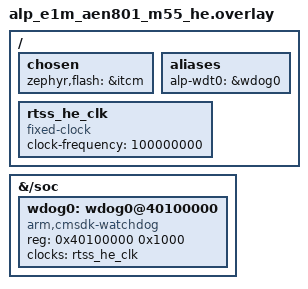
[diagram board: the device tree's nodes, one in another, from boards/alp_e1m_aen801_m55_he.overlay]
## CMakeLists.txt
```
# SPDX-License-Identifier: Apache-2.0
cmake_minimum_required(VERSION 3.20)
find_package(Zephyr REQUIRED HINTS $ENV{ZEPHYR_BASE})
project(aen_wdt_feed LANGUAGES C)
target_sources(app PRIVATE src/main.c)
```

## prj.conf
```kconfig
# SPDX-License-Identifier: Apache-2.0
#
# Bench RAM-run config for the E1M-AEN801 (M55-HE).

CONFIG_ALP_SDK=y

# Watchdog subsystem + the UPSTREAM CMSDK driver. CONFIG_WDOG_CMSDK_APB is
# `default y` once the wdog0 node is enabled (DT_HAS_ARM_CMSDK_WATCHDOG_ENABLED);
# it depends on RUNTIME_NMI (the CMSDK WDT signals via NMI).
CONFIG_WATCHDOG=y
CONFIG_RUNTIME_NMI=y

CONFIG_MAIN_STACK_SIZE=4096

# Console: Alp UART console -- E1M edge UART0 (Alif UART5, P3_4/P3_5, 115200
# 8N1, NS16550), the E1M-AEN801 carrier console. The board _defconfig already
# selects it; we set it explicitly here so the example is self-describing.
CONFIG_SERIAL=y
CONFIG_CONSOLE=y
CONFIG_UART_CONSOLE=y
CONFIG_UART_INTERRUPT_DRIVEN=y
# Serial-less bench? Comment the four lines above and uncomment these to read
# 'ram_console_buf' over SWD instead:
# CONFIG_RAM_CONSOLE=y
# CONFIG_RAM_CONSOLE_BUFFER_SIZE=2048
# CONFIG_UART_CONSOLE=n
CONFIG_PRINTK=y
```

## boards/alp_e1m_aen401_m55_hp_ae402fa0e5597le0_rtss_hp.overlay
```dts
/*
 * Copyright (c) 2026 Alp Lab AB
 * SPDX-License-Identifier: Apache-2.0
 *
 * CMSDK watchdog overlay for the E1M-AEN401 (E4, M55-HP).
 *
 * The board devicetree carries wdog0@40100000 (arm,cmsdk-watchdog) and its
 * clock, disabled (zephyr/dts/alif/ensemble_rtss_hp_wdog.dtsi); this overlay
 * only enables it and names it for the app.  Driver = UPSTREAM Zephyr
 * wdt_cmsdk_apb.c (Tier-1, NOT vendored).
 */

/ {
	chosen {
		zephyr,flash = &itcm; /* bench RAM/SES-load; path-ref form */
		/delete-property/ zephyr,code-partition;
	};
	aliases {
		alp-wdt0 = &wdog0;
	};
};

&wdog0 {
	status = "okay";
};
```

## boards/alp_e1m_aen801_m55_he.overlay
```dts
/*
 * Copyright (c) 2026 Alp Lab AB
 * SPDX-License-Identifier: Apache-2.0
 *
 * CMSDK watchdog overlay for the E1M-AEN801 (E8, M55-HE).
 *
 * wdog0@40100000 (compatible arm,cmsdk-watchdog) is transcribed from the
 * Apache-2.0 zephyr_alif fork (dts/arm/alif/ensemble RTSS-HE) -- the alp-sdk E8
 * SoC dtsi doesn't carry it, so it is created here.  Driver = UPSTREAM Zephyr
 * wdt_cmsdk_apb.c (Tier-1, NOT vendored).
 *
 * The driver reads its tick rate from the `clocks` phandle's `clock-frequency`
 * property at build time (DT_INST_PROP_BY_PHANDLE(0, clocks, clock_frequency)),
 * so we add a fixed-clock `rtss_he_clk` -- the same phandle the fork uses on the
 * HE core.  Its frequency is a TRM PLACEHOLDER: reload = timeout_ms * freq_khz,
 * so the API path is exact but the absolute timeout DURATION is unverified until
 * the real RTSS-HE watchdog clock is confirmed. [[project_pending_hw_configs]]
 */

/ {
	chosen {
		zephyr,flash = &itcm; /* bench RAM/SES-load; path-ref form */
		/delete-property/ zephyr,code-partition;
	};
	aliases {
		alp-wdt0 = &wdog0;
	};

	rtss_he_clk: rtss_he_clk {
		compatible = "fixed-clock";
		#clock-cells = <0>;
		clock-frequency = <100000000>; /* PLACEHOLDER; confirm vs TRM */
	};
};

&{/soc} {
	wdog0: wdog0@40100000 {
		compatible = "arm,cmsdk-watchdog";
		reg = <0x40100000 0x1000>;
		clocks = <&rtss_he_clk>;
		status = "okay";
	};
};
```

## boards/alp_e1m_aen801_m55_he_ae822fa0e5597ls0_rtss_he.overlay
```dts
/*
 * Copyright (c) 2026 Alp Lab AB
 * SPDX-License-Identifier: Apache-2.0
 *
 * CMSDK watchdog overlay for the E1M-AEN801 (E8, M55-HE).
 *
 * The board devicetree carries wdog0@40100000 (arm,cmsdk-watchdog) and its
 * clock, disabled (zephyr/dts/alif/ensemble_rtss_he_wdog.dtsi); this overlay
 * only enables it and names it for the app.  Driver = UPSTREAM Zephyr
 * wdt_cmsdk_apb.c (Tier-1, NOT vendored).
 */

/ {
	chosen {
		zephyr,flash = &itcm; /* bench RAM/SES-load; path-ref form */
		/delete-property/ zephyr,code-partition;
	};
	aliases {
		alp-wdt0 = &wdog0;
	};
};

&wdog0 {
	status = "okay";
};
```

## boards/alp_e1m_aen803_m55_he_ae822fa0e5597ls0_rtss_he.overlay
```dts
/*
 * Copyright (c) 2026 Alp Lab AB
 * SPDX-License-Identifier: Apache-2.0
 *
 * CMSDK watchdog overlay for the E1M-AEN803 (E8, M55-HE).
 *
 * The board devicetree carries wdog0@40100000 (arm,cmsdk-watchdog) and its
 * clock, disabled (zephyr/dts/alif/ensemble_rtss_he_wdog.dtsi); this overlay
 * only enables it and names it for the app.  Driver = UPSTREAM Zephyr
 * wdt_cmsdk_apb.c (Tier-1, NOT vendored).
 */

/ {
	chosen {
		zephyr,flash = &itcm; /* bench RAM/SES-load; path-ref form */
		/delete-property/ zephyr,code-partition;
	};
	aliases {
		alp-wdt0 = &wdog0;
	};
};

&wdog0 {
	status = "okay";
};
```

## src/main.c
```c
/*
 * Copyright (c) 2026 Alp Lab AB
 * SPDX-License-Identifier: Apache-2.0
 *
 * aen-wdt-feed -- install + feed the Ensemble E4 / E8 CMSDK watchdog on the
 * E1M-AEN801/803 (M55-HE) or E1M-AEN401 (M55-HP), via the UPSTREAM Zephyr
 * wdt_cmsdk_apb driver (Tier-1, no vendoring -- "arm,cmsdk-watchdog").  Drives
 * the standard Zephyr watchdog API (wdt_install_timeout / wdt_setup / wdt_feed /
 * wdt_disable) on DT_ALIAS(alp_wdt0) = &wdog0.
 *
 * The watchdog is the safety belt: if the main loop hangs, the WDT resets the
 * SoC back to a known-good state.  This example installs a timeout, feeds it a
 * few times, then DISABLES it -- it never lets the timeout actually fire (a
 * reset would re-boot the SES and tear down the bench RAM-console read).
 *
 * PASS gate: device ready, wdt_install_timeout + wdt_setup + every wdt_feed
 * return 0, and wdt_disable returns 0 (the WDT was running and got stopped
 * cleanly).  NOTE: the exact timeout duration depends on the watchdog clock
 * rate, which is a TRM placeholder here -- the API path is what this proves.
 */

#include <stdio.h>

#include <alp/peripheral.h>
#include <zephyr/device.h>
#include <zephyr/drivers/watchdog.h>

#define WDT_NODE       DT_ALIAS(alp_wdt0)
#define WDT_TIMEOUT_MS 8000
#define FEEDS          5
#define FEED_PERIOD_MS 300

int main(void)
{
	const struct device *wdt = DEVICE_DT_GET(WDT_NODE);

	printf("[wdt] open %s (CMSDK watchdog, timeout=%u ms)\n", wdt->name, WDT_TIMEOUT_MS);
	if (!device_is_ready(wdt)) {
		printf("[wdt] RESULT FAIL: device not ready\n[wdt] done\n");
		return 0;
	}

	struct wdt_timeout_cfg cfg = {
		.window   = { .min = 0, .max = WDT_TIMEOUT_MS },
		.callback = NULL,
		.flags    = WDT_FLAG_RESET_SOC,
	};
	int ch = wdt_install_timeout(wdt, &cfg);
	printf("[wdt] wdt_install_timeout -> %d\n", ch);
	if (ch < 0) {
		printf("[wdt] RESULT FAIL: install rc=%d\n[wdt] done\n", ch);
		return 0;
	}

	/* PAUSE_HALTED_BY_DBG so the SWD halt used to read the console doesn't
	 * trip the watchdog mid-debug. */
	int rc = wdt_setup(wdt, WDT_OPT_PAUSE_HALTED_BY_DBG);
	printf("[wdt] wdt_setup -> %d\n", rc);
	if (rc != 0) {
		printf("[wdt] RESULT FAIL: setup rc=%d\n[wdt] done\n", rc);
		return 0;
	}

	int fed = 0;
	for (int i = 0; i < FEEDS; i++) {
		alp_delay_ms(FEED_PERIOD_MS);
		rc = wdt_feed(wdt, ch);
		if (rc != 0) {
			printf("[wdt] wdt_feed[%d] -> %d\n", i, rc);
			break;
		}
		fed++;
		printf("[wdt] fed %d/%d\n", fed, FEEDS);
	}

	/* Stop the watchdog before main() returns so the SoC doesn't reset out
	 * from under the bench console read. */
	rc = wdt_disable(wdt);
	printf("[wdt] wdt_disable -> %d\n", rc);

	bool ok = (fed == FEEDS) && (rc == 0);
	printf("[wdt] RESULT %s: %s\n",
	       ok ? "PASS" : "PARTIAL",
	       ok ? "install + setup + feed x5 + disable all clean (exact timeout pends WDT clock rate)"
	          : "WDT path incomplete (see rc above)");
	printf("[wdt] done\n");
	return 0;
}
```
